# ATSAM4SA16B register map
Vendor: Atmel; File version: 0
CPU: CM4 r0p1, selectable endian, no MPU, no FPU, 0x4 interrupt priority bits, 0x0 interrupts
Registers are 32-bit, read-write, no defined reset value unless marked. A register's access mark holds for its fields unless they carry their own. Offsets are from the block's base; [hi:lo] are bit positions.

## TWI0 — Two-wire Interface 0
Base 0x40018000; register names take the prefix TWI0_
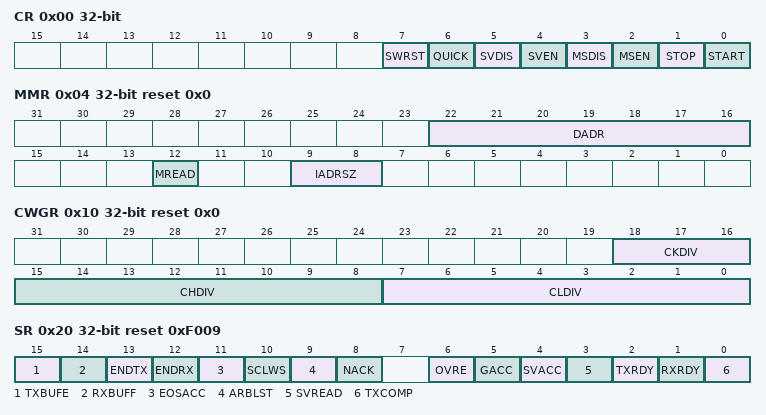
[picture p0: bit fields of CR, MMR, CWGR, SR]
0x00 CR wo — Control Register
  [7] SWRST — Software Reset
  [6] QUICK — SMBus Quick Command
  [5] SVDIS — TWI Slave Mode Disabled
  [4] SVEN — TWI Slave Mode Enabled
  [3] MSDIS — TWI Master Mode Disabled
  [2] MSEN — TWI Master Mode Enabled
  [1] STOP — Send a STOP Condition
  [0] START — Send a START Condition
0x04 MMR reset 0x0 — Master Mode Register
  [22:16] DADR — Device Address
  [12] MREAD — Master Read Direction
  [9:8] IADRSZ — Internal Device Address Size
    0=NONE (No internal device address); 1=1_BYTE (One-byte internal device address); 2=2_BYTE (Two-byte internal device address); 3=3_BYTE (Three-byte internal device address)
0x08 SMR reset 0x0 — Slave Mode Register
  [22:16] SADR — Slave Address
0x0C IADR reset 0x0 — Internal Address Register
  [23:0] IADR — Internal Address
0x10 CWGR reset 0x0 — Clock Waveform Generator Register
  [18:16] CKDIV — Clock Divider
  [15:8] CHDIV — Clock High Divider
  [7:0] CLDIV — Clock Low Divider
0x20 SR ro reset 0xF009 — Status Register
  [15] TXBUFE — TX Buffer Empty (cleared by writing TWI_TCR or TWI_TNCR)
  [14] RXBUFF — RX Buffer Full (cleared by writing TWI_RCR or TWI_RNCR)
  [13] ENDTX — End of TX buffer (cleared by writing TWI_TCR or TWI_TNCR)
  [12] ENDRX — End of RX buffer (cleared by writing TWI_RCR or TWI_RNCR)
  [11] EOSACC — End Of Slave Access (cleared on read)
  [10] SCLWS — Clock Wait State
  [9] ARBLST — Arbitration Lost (cleared on read)
  [8] NACK — Not Acknowledged (cleared on read)
  [6] OVRE — Overrun Error (cleared on read)
  [5] GACC — General Call Access (cleared on read)
  [4] SVACC — Slave Access
  [3] SVREAD — Slave Read
  [2] TXRDY — Transmit Holding Register Ready (cleared by writing TWI_THR)
  [1] RXRDY — Receive Holding Register Ready (cleared by reading TWI_RHR)
  [0] TXCOMP — Transmission Completed (cleared by writing TWI_THR)
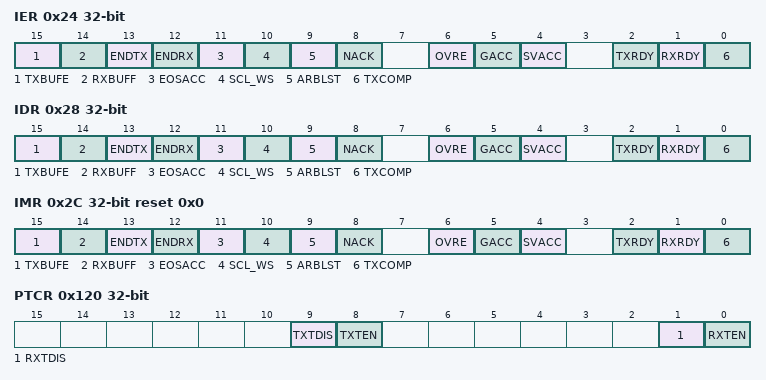
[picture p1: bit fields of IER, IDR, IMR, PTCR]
0x24 IER wo — Interrupt Enable Register
  [15] TXBUFE — Transmit Buffer Empty Interrupt Enable
  [14] RXBUFF — Receive Buffer Full Interrupt Enable
  [13] ENDTX — End of Transmit Buffer Interrupt Enable
  [12] ENDRX — End of Receive Buffer Interrupt Enable
  [11] EOSACC — End Of Slave Access Interrupt Enable
  [10] SCL_WS — Clock Wait State Interrupt Enable
  [9] ARBLST — Arbitration Lost Interrupt Enable
  [8] NACK — Not Acknowledge Interrupt Enable
  [6] OVRE — Overrun Error Interrupt Enable
  [5] GACC — General Call Access Interrupt Enable
  [4] SVACC — Slave Access Interrupt Enable
  [2] TXRDY — Transmit Holding Register Ready Interrupt Enable
  [1] RXRDY — Receive Holding Register Ready Interrupt Enable
  [0] TXCOMP — Transmission Completed Interrupt Enable
0x28 IDR wo — Interrupt Disable Register
  [15] TXBUFE — Transmit Buffer Empty Interrupt Disable
  [14] RXBUFF — Receive Buffer Full Interrupt Disable
  [13] ENDTX — End of Transmit Buffer Interrupt Disable
  [12] ENDRX — End of Receive Buffer Interrupt Disable
  [11] EOSACC — End Of Slave Access Interrupt Disable
  [10] SCL_WS — Clock Wait State Interrupt Disable
  [9] ARBLST — Arbitration Lost Interrupt Disable
  [8] NACK — Not Acknowledge Interrupt Disable
  [6] OVRE — Overrun Error Interrupt Disable
  [5] GACC — General Call Access Interrupt Disable
  [4] SVACC — Slave Access Interrupt Disable
  [2] TXRDY — Transmit Holding Register Ready Interrupt Disable
  [1] RXRDY — Receive Holding Register Ready Interrupt Disable
  [0] TXCOMP — Transmission Completed Interrupt Disable
0x2C IMR ro reset 0x0 — Interrupt Mask Register
  [15] TXBUFE — Transmit Buffer Empty Interrupt Mask
  [14] RXBUFF — Receive Buffer Full Interrupt Mask
  [13] ENDTX — End of Transmit Buffer Interrupt Mask
  [12] ENDRX — End of Receive Buffer Interrupt Mask
  [11] EOSACC — End Of Slave Access Interrupt Mask
  [10] SCL_WS — Clock Wait State Interrupt Mask
  [9] ARBLST — Arbitration Lost Interrupt Mask
  [8] NACK — Not Acknowledge Interrupt Mask
  [6] OVRE — Overrun Error Interrupt Mask
  [5] GACC — General Call Access Interrupt Mask
  [4] SVACC — Slave Access Interrupt Mask
  [2] TXRDY — Transmit Holding Register Ready Interrupt Mask
  [1] RXRDY — Receive Holding Register Ready Interrupt Mask
  [0] TXCOMP — Transmission Completed Interrupt Mask
0x30 RHR ro reset 0x0 — Receive Holding Register
  [7:0] RXDATA — Master or Slave Receive Holding Data
0x34 THR wo — Transmit Holding Register
  [7:0] TXDATA — Master or Slave Transmit Holding Data
0x100 RPR reset 0x0 — Receive Pointer Register
  [31:0] RXPTR
0x104 RCR reset 0x0 — Receive Counter Register
  [15:0] RXCTR
0x108 TPR reset 0x0 — Transmit Pointer Register
  [31:0] TXPTR — Transmit Counter Register
0x10C TCR reset 0x0 — Transmit Counter Register
  [15:0] TXCTR
0x110 RNPR reset 0x0 — Receive Next Pointer Register
  [31:0] RXNPTR — Receive Next Pointer
0x114 RNCR reset 0x0 — Receive Next Counter Register
  [15:0] RXNCTR — Receive Next Counter
0x118 TNPR reset 0x0 — Transmit Next Pointer Register
  [31:0] TXNPTR — Transmit Next Pointer
0x11C TNCR reset 0x0 — Transmit Next Counter Register
  [15:0] TXNCTR — Transmit Counter Next
0x120 PTCR wo — Transfer Control Register
  [9] TXTDIS — Transmitter Transfer Disable
  [8] TXTEN — Transmitter Transfer Enable
  [1] RXTDIS — Receiver Transfer Disable
  [0] RXTEN — Receiver Transfer Enable
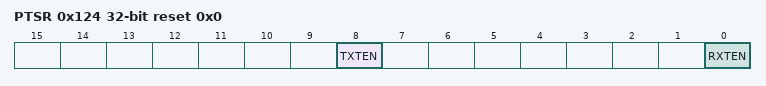
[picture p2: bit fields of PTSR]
0x124 PTSR ro reset 0x0 — Transfer Status Register
  [8] TXTEN — Transmitter Transfer Enable
  [0] RXTEN — Receiver Transfer Enable

## TWI1 — Two-wire Interface 1
Base 0x4001C000; register names take the prefix TWI1_
Registers as TWI0.
